# a34m41x register map
Vendor: ABOV Semiconductor Co., Ltd.; File version: 1.0
CPU: CM4 r0p1, little endian, MPU, FPU, VTOR, 4 interrupt priority bits
Registers are 32-bit, read-write, reset 0x0 unless marked. A register's access mark holds for its fields unless they carry their own. Offsets are from the block's base; [hi:lo] are bit positions; {n}, {i} and the like mark numbered series.

## TIMER0 — TIMER COUNTER
Base 0x40003000
Same registers: TIMER{n} {0x40003000+0x40*n} (n=1..9)
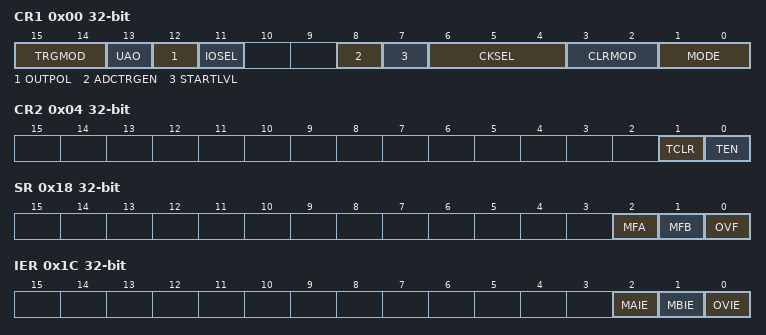
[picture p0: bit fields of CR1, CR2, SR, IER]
0x00 CR1 — Timer Control Register1
  [15:14] TRGMOD — Timer ADC Trigger Mode Selection Bit
    0=GRA (GRA Value Trigger Mode (Normal Mode)); 2=TRGPNT (TRGPNT Value Trigger Mode); 3=GRA_TRGPNT (GRA, TRGPNT Value Both Trigger Mode)
  [13] UAO — GRA, GRB Update Mode Selection bit
    0=Next_Period (Write Value Apply to next period); 1=Current_Period (Write value apply to current period)
  [12] OUTPOL — TIMER Output Polarity Selection Bit
    0=Normal Output; 1=Polarity (Polairty Output)
  [11] IOSEL — TIMER Input/Output Selection Bit
    0=Input (Timer Input Port Setting); 1=Output (Timer Output Port Setting)
  [8] ADCTRGEN — ADC Trigger Source Enable Bit
    0=NoUsed; 1=Used
  [7] STARTLVL — Interval/PWM/One-shot Mode Initial output value setting
    0=Low (Output Start Low); 1=High (Output Start High)
  [6:4] CKSEL — Timer Clock Source Selection bit
    0=PCLK_DIV2 (Counter Clock is PCLK/2); 1=PCLK_DIV4 (Counter Clock is PCLK/4); 2=PCLK_DIV16 (Counter Clock is PCLK/16); 3=PCLK_DIV64 (Counter Clock is PCLK/64); 4=EXT0_MCCR3 (Counter Clock is EXT0(MCCR3)); 6=TnC (Counter Clock is TnC (input pin))
  [3:2] CLRMOD — Capture Mode Clear Selection bit
    0=Rising Edge Clear Mode; 1=Falling Edge Clear Mode; 2=Both (Rising/Falling Edge Clear Mode); 3=Not Clear Mode
  [1:0] MODE — TIMER Operating Mode Control Bit
    0=Interval (Timer is Interval Mode); 1=PWM (Timer is PWM Mode); 2=Oneshot (Timer is One-Shot Mode); 3=Capture (Timer is Capture Mode)
0x04 CR2 — Timer Control Register2
  [1] TCLR wo — Timer Counter Register Clear Bit
  [0] TEN — Timer Counter
    0=Disable (Timer Disable); 1=Enable (Timer Enable)
0x08 PRS — Timer Prescaler Register
  [9:0] PRS — Counter Clock Prescaler Value, TCLK=CLOCK_IN/(PRS+1)
0x0C GRA — Timer General Data Register A
  [15:0] GRA — GRA Value Bit
0x10 GRB — Timer General Data Register B
  [15:0] GRB — GRB Balue Bit
0x14 CNT — Timer Counter Register
  [15:0] CNT — Timer Counter bits.
0x18 SR — Timer Status Register
  [2] MFA — GRA Match Flag
  [1] MFB — GRB Match Flag
  [0] OVF — Counter Overflow Flag
0x1C IER — Timer Interrupt Enable Register
  [2] MAIE — GRA Match Interrupt Enable bit
  [1] MBIE — GRB Match Interrupt Enable bit
  [0] OVIE — Counter Overflow Interrupt Enable bit
0x20 TRGPNT — Timer Trigger Point Register
  [15:0] TRGPNT — Timer Trigger Point Value Bit
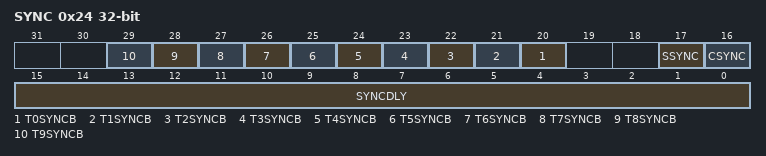
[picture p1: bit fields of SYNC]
0x24 SYNC — Timer Sync Setting Register
  [n+20] T{n}SYNCB (n=0..9) — Timer {n} sync enable bit
    0=Disable (SYNC Disable); 1=Enable (SYNC Enable)
  [17] SSYNC — Timer n Counter Start Sync
    0=Disable (SYNC Disable); 1=Enable (SYNC Enable)
  [16] CSYNC — Timer n Counter Clear Sync
    0=Disable (SYNC Disable); 1=Enable (SYNC Enable)
  [15:0] SYNCDLY — SYNC Delay Counter Value Setting Bit

## FRT0 — Free Run Timer
Base 0x40000600
Same registers: FRT1 0x40000700
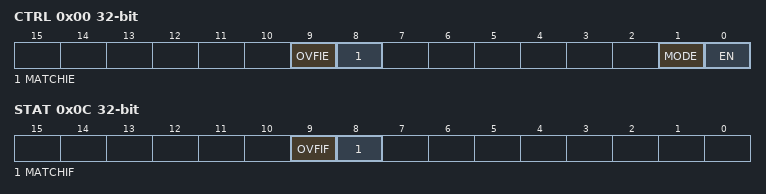
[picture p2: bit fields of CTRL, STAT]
0x00 CTRL — FRT n Control Register
  [9] OVFIE — Over Flow Interrupt Enable bit
    0=Disable (Interrupt Disable); 1=Enable (Interrupt Enable)
  [8] MATCHIE — Match Interrupt Enable Bit
    0=Disable (Interrupt Disable); 1=Enable (Interrupt Enable)
  [1] MODE — FRT Mode Selection Bit
    0=FreeRunTimer; 1=MatchTimer
  [0] EN — FRT Enable Bit
    0=Disable (FRT Disable); 1=Enable (FRT Enable)
0x04 MCNT — FRT n Match Counter Register
  [31:0] MCNT — Match Counter Bit
0x08 CNT — FRT n Counter Register
  [31:0] CNT — Counter Bit *only write '0x0'
0x0C STAT — FRT n Status Register
  [9] OVFIF — Overflow Interrupt Status
  [8] MATCHIF — Match Interrupt Status

## UART0 — Universal Asynchronous Receiver/Transmitter
Base 0x40008000
Same registers: UART1 0x40008100, UART2 0x40008200, UART3 0x40008300, UART4 0x40008400, UART5 0x40008500
0x00 RBR ro — UARTn Receive Data Buffer Register
  [7:0] RBR
0x00 THR wo — UARTn Transmit Data Hold Register
  [7:0] THR
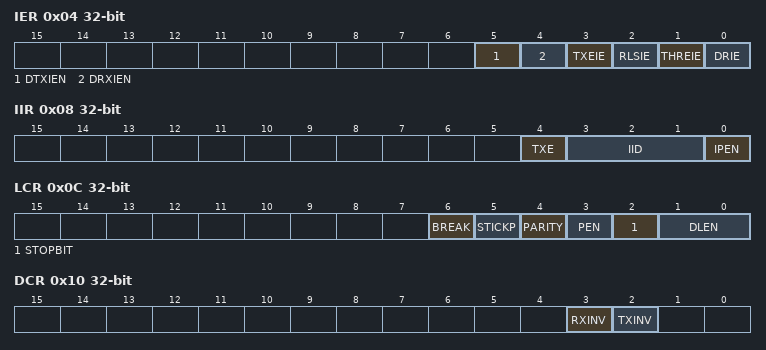
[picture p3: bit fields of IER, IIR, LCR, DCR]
0x04 IER — UARTn Interrupt Enable Register
  [5] DTXIEN — DMA Transmitter complete interrupt allow
  [4] DRXIEN — DMA Receiver over Interrupt allow
  [3] TXEIE — Transmit Empty Interrupt Enable bit
  [2] RLSIE — Receiver Line Status Interrupt Enable bit
  [1] THREIE — Transmit Holding Register Empty Interrupt Enable bit
  [0] DRIE — Data Receive Interrupt Enable bit
0x08 IIR ro — UARTn Interrupt ID Register
  [4] TXE — Transmit Complete Interrupt Source ID bit
  [3:1] IID — UARTn Interrupt ID bits. Note: The UARTn supports 3-priority interrupt generation and the interrupt source ID register shows one interrupt source which has highest priority among pending interrupts. The priority is defined as below. - Receive line status interrupt - Receive data ready interrupt and Character timeout interrupt - Transmit hold register empty interrupt
  [0] IPEN — Interrupt Pending bit
0x0C LCR — UARTn Line Control Register
  [6] BREAK — Transfer Break Control bit. The TXDn pin will be driven at low state in order to notice
  [5] STICKP — Force Parity bit. This bit is effective when the PEN bit is set to "1b"
  [4] PARITY — Parity Mode and Parity Stuck Selection bit
  [3] PEN — Parity Bit Transfer Enable bit
  [2] STOPBIT — Stop Bit Length Selection bit
  [1:0] DLEN — Data Length Selection bits
    {v}={v+5}bit data (v=0..3)
0x10 DCR — UARTn Data Control Register
  [3] RXINV — Rx Data Polarity selection
  [2] TXINV — Transmit Data Inversion Selection bit
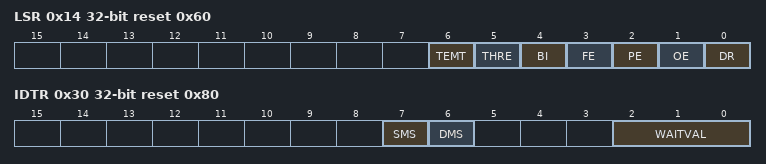
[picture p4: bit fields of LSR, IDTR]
0x14 LSR ro reset 0x60 — UARTn Line Status Register
  [6] TEMT — Transmit Empty bit
  [5] THRE — Transmit Holding Empty bit. Note: This bit will be set to "1b" when it starts transmit.
  [4] BI — Break Condition Indication bit
  [3] FE — Frame Error Indicator bit
  [2] PE — Parity Error Indicator bit
  [1] OE — Overrun Error Indicator bit
  [0] DR — Data Receive Indicator bit
0x20 BDR — UARTn Baud Rate Divisor Latch Register
  [15:0] BDR — Baud Rate Divider Latch Value. Baud rate = fUARTnCLK/(16 x BDR[15:0] x 2). Note: The UART block won't work if the BDR[15:0] == 0x0000.
0x24 BFR — UARTn Baud Rate Fractional Counter Value
  [7:0] BFR — Fraction Counter value. 0 = Disable fraction counter N = Fraction compensation mode is operating. Fraction counter is incremented by FCNT. FCNT = Float * 256 Note: 8-bit fractional counter will count up by FCNT value every (baud rate)/16 period and whenever fractional counter overflow is happen, the divisor value will increment by 1. So this period will be compensated. Then next period, the divisor value will return to original set value.
    0=DISABLE_FRACTION_COUNTER
0x30 IDTR reset 0x80 — UARTn Inter-frame Delay Time Register
  [7] SMS — Start Bit Multi Sampling Enable bit
  [6] DMS — Data Bit Multi sampling enable
  [2:0] WAITVAL — Wait Time Value. Dummy delay can be inserted between 2 Continuous Transmits. Wait Time = WAITVAL[2:0]/(Baud Rate)
